# ing916 register map
Vendor: INGChips; Series: ing916xx; File version: 522
CPU: CM4 r0p1, little endian, MPU, FPU, VTOR, 5 interrupt priority bits
Registers are 32-bit, read-write, reset 0x0 unless marked. A register's access mark holds for its fields unless they carry their own. Offsets are from the block's base; [hi:lo] are bit positions; {n}, {i} and the like mark numbered series.

## key_scanner
Base 0x4000A000
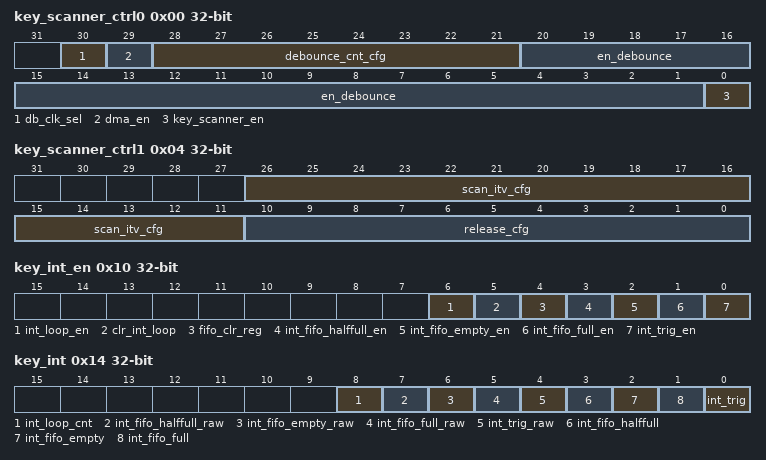
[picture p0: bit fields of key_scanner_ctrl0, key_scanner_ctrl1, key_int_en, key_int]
0x00 key_scanner_ctrl0 — reg description:
  [30] db_clk_sel — reg description:
  [29] dma_en — reg description:
  [28:21] debounce_cnt_cfg — reg description:
  [20:1] en_debounce — reg description:
  [0] key_scanner_en — reg description:
0x04 key_scanner_ctrl1 — reg description:
  [26:11] scan_itv_cfg — reg description:
  [10:0] release_cfg — reg description:
0x08 key_row_mask_ctrl — reg description:
  [19:0] key_mask_row
0x0C key_col_mask_ctrl — reg description:
  [19:0] key_mask_col
0x10 key_int_en — reg description:
  [6] int_loop_en — reg description:
  [5] clr_int_loop — reg description:
  [4] fifo_clr_reg — reg description:
  [3] int_fifo_halffull_en — reg description:
  [2] int_fifo_empty_en — reg description:
  [1] int_fifo_full_en — reg description:
  [0] int_trig_en — reg description:
0x14 key_int — reg description:
  [8] int_loop_cnt — reg description:
  [7] int_fifo_halffull_raw — reg description:
  [6] int_fifo_empty_raw — reg description:
  [5] int_fifo_full_raw — reg description:
  [4] int_trig_raw — reg description:
  [3] int_fifo_halffull — reg description:
  [2] int_fifo_empty — reg description:
  [1] int_fifo_full — reg description:
  [0] int_trig — reg description:
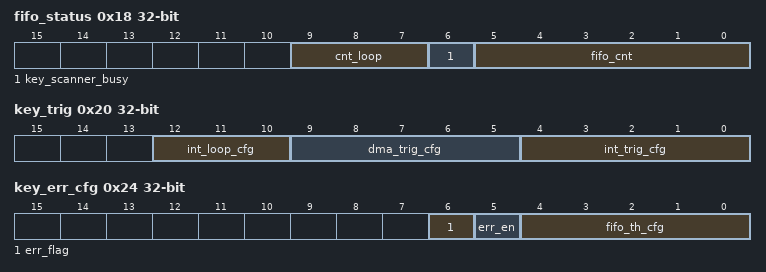
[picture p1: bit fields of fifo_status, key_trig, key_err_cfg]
0x18 fifo_status — reg description:
  [9:7] cnt_loop — reg description:
  [6] key_scanner_busy — reg description:
  [5:0] fifo_cnt — reg description:
0x1C key_data — reg description:
  [10:0] key_data
0x20 key_trig — reg description:
  [12:10] int_loop_cfg — reg description:
  [9:5] dma_trig_cfg — reg description:
  [4:0] int_trig_cfg — reg description:
0x24 key_err_cfg — reg description:
  [6] err_flag — reg description:
  [5] err_en — reg description:
  [4:0] fifo_th_cfg — reg description:

## pwm
Base 0x40005000
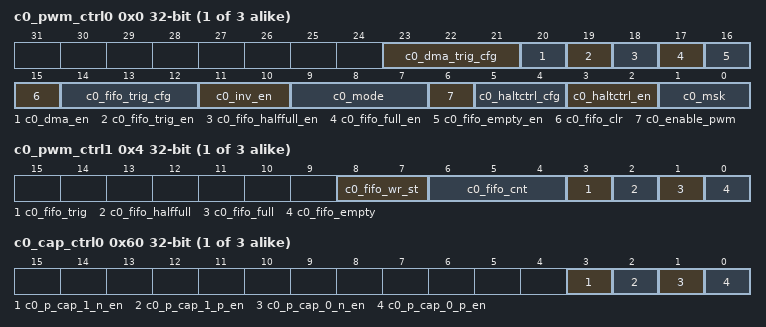
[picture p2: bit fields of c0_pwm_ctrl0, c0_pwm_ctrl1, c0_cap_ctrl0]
{0x0+0x20*i} c{i}_pwm_ctrl0 (i=0..2) — reg description:
  [23:21] c{i}_dma_trig_cfg — reg description:
  [20] c{i}_dma_en — reg description:
  [19] c{i}_fifo_trig_en — reg description:
  [18] c{i}_fifo_halffull_en — reg description:
  [17] c{i}_fifo_full_en — reg description:
  [16] c{i}_fifo_empty_en — reg description:
  [15] c{i}_fifo_clr — reg description:
  [14:12] c{i}_fifo_trig_cfg — reg description:
  [11:10] c{i}_inv_en — reg description:
  [9:7] c{i}_mode — reg description:
  [6] c{i}_enable_pwm — reg description:
  [5:4] c{i}_haltctrl_cfg — reg description:
  [3:2] c{i}_haltctrl_en — reg description:
  [1:0] c{i}_msk — reg description:
{0x4+0x20*i} c{i}_pwm_ctrl1 (i=0..2) — reg description:
  [8:7] c{i}_fifo_wr_st — reg description:
  [6:4] c{i}_fifo_cnt — reg description:
  [3] c{i}_fifo_trig — reg description:
  [2] c{i}_fifo_halffull — reg description:
  [1] c{i}_fifo_full — reg description:
  [0] c{i}_fifo_empty — reg description:
{0x10+0x20*i} c{i}_pwm_ctrl2 (i=0..2) — reg description:
  [19:0] c{i}_pera_th
{0x14+0x20*i} c{i}_pwm_ctrl3 (i=0..2) — reg description:
  [19:0] c{i}_high_th
{0x18+0x20*i} c{i}_pwm_ctrl4 (i=0..2) — reg description:
  [19:0] c{i}_dzone_th
{0x1C+0x20*i} c{i}_pwm_ctrl5 (i=0..2) — reg description:
  [19:0] c{i}_dma_data
{0x60+0x10*i} c{i}_cap_ctrl0 (i=0..2) — reg description:
  [3] c{i}_p_cap_1_n_en — reg description:
  [2] c{i}_p_cap_1_p_en — reg description:
  [1] c{i}_p_cap_0_n_en — reg description:
  [0] c{i}_p_cap_0_p_en — reg description:
{0x64+0x10*i} c{i}_cap_ctrl1 (i=0..2) — reg description:
  [31:0] c{i}_cap_data
0x90 cap_cnt_en — reg description:
  [0] cap_cnt_en
0x94 cap_cnt — reg description:

## efuse
Base 0x40017000
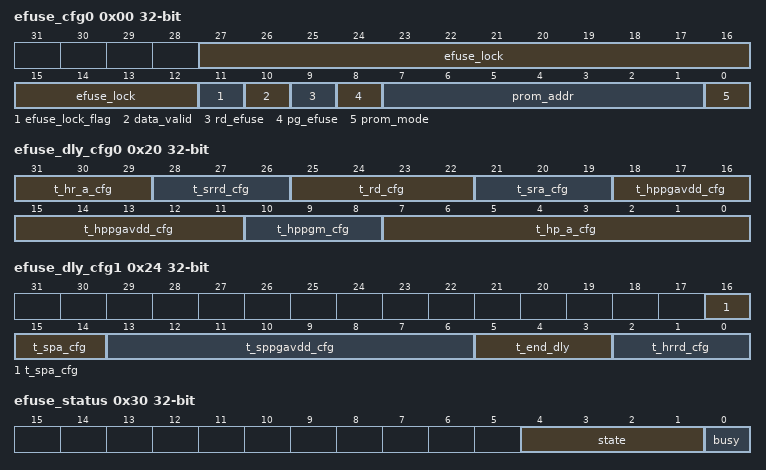
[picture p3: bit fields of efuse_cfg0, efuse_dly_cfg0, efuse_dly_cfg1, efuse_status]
0x00 efuse_cfg0 — reg description:
  [27:12] efuse_lock — reg description:
  [11] efuse_lock_flag — reg description:
  [10] data_valid — reg description:
  [9] rd_efuse — reg description:
  [8] pg_efuse — reg description:
  [7:1] prom_addr — reg description:
  [0] prom_mode — reg description:
{0x0+4i} efuse_cfg{i} (i=1..3) — reg description:
  [31:0] prom_cfg{i-1}
0x1C efuse_cfg4 — reg description:
  [31:0] prom_cfg3
0x20 efuse_dly_cfg0 — reg description:
  [31:29] t_hr_a_cfg — reg description:
  [28:26] t_srrd_cfg — reg description:
  [25:22] t_rd_cfg — reg description:
  [21:19] t_sra_cfg — reg description:
  [18:11] t_hppgavdd_cfg — reg description:
  [10:8] t_hppgm_cfg — reg description:
  [7:0] t_hp_a_cfg — reg description:
0x24 efuse_dly_cfg1 — reg description:
  [16:14] t_spa_cfg — reg description:
  [13:6] t_sppgavdd_cfg — reg description:
  [5:3] t_end_dly — reg description:
  [2:0] t_hrrd_cfg — reg description:
0x30 efuse_status — reg description:
  [4:1] state — reg description:
  [0] busy — reg description:
{0x40+4i} efuse_rdata{i} (i=0..3) — reg description:
  [31:0] rdata_efuse{i}
